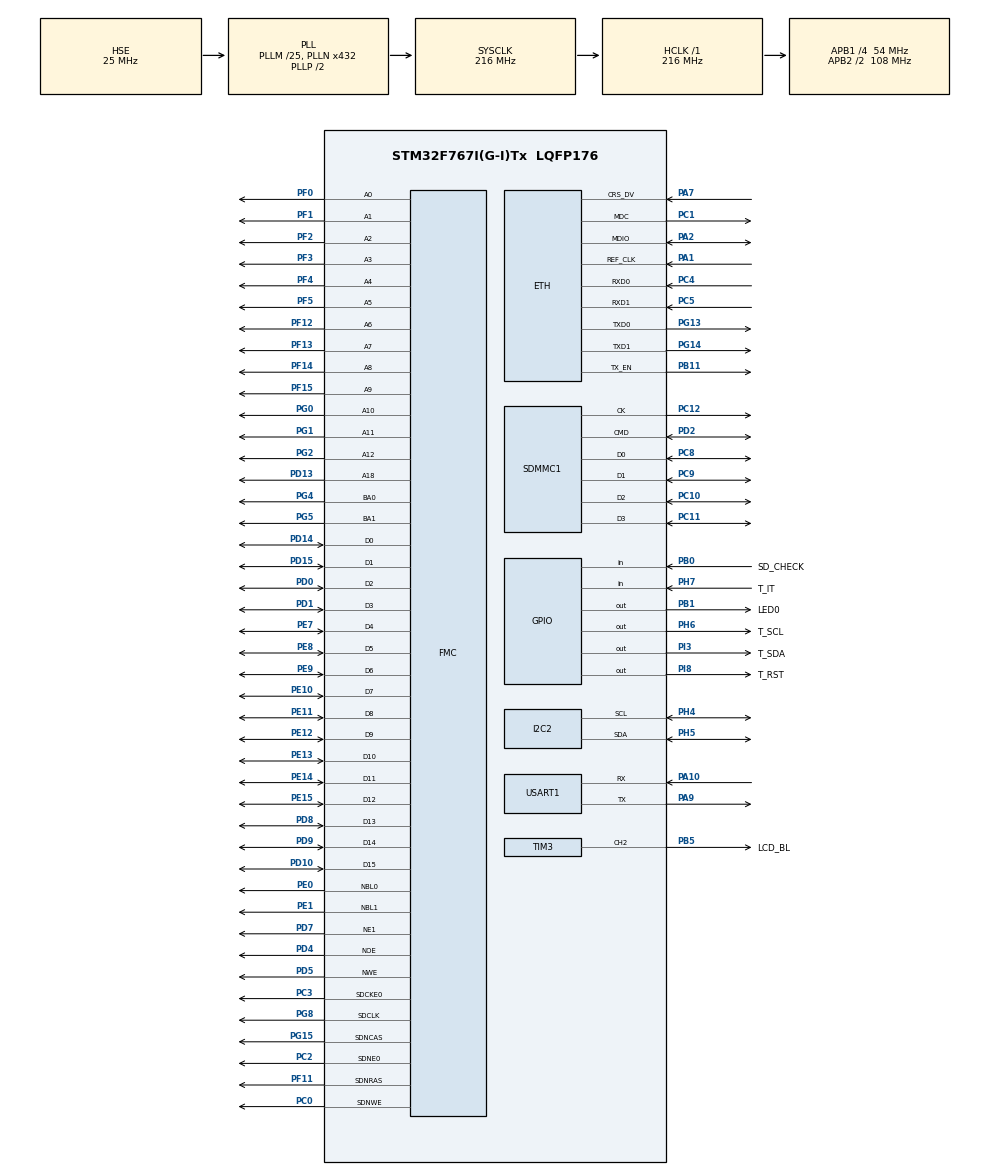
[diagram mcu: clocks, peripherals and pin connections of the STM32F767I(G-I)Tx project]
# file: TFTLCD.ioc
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PD7.Mode=NorPsramChipSelect1_1
SH.FMC_D7_DA7.1=FMC_D7,sd-16b-d1
SH.FMC_D7_DA7.0=FMC_D7,16b-d1
FATFS._USE_LFN=2
FMC.RCDDelay1=6
Dma.SDMMC1_RX.0.MemInc=DMA_MINC_ENABLE
FMC.SDClockPeriod1=FMC_SDRAM_CLOCK_PERIOD_2
SH.FMC_A0.0=FMC_A0,13b-sda1
FATFS0.BSP.api=Unknown
VP_FATFS_VS_SDIO.Mode=SDIO
PG8.Signal=FMC_SDCLK
PG4.Signal=FMC_A14_BA0
PC12.Signal=SDMMC1_CK
PH6.GPIO_Label=T_SCL
PG0.Signal=FMC_A10
FMC.LoadToActiveDelay1=2
PC5.Mode=RMII
SH.FMC_D5_DA5.1=FMC_D5,sd-16b-d1
SH.FMC_D5_DA5.0=FMC_D5,16b-d1
PG13.Signal=ETH_TXD0
SH.FMC_NWE.0=FMC_NWE,Lcd1
RCC.SYSCLKSource=RCC_SYSCLKSOURCE_PLLCLK
SH.FMC_A15_BA1.0=FMC_BA1,FourSdramBanks1
SH.FMC_D9_DA9.0=FMC_D9,16b-d1
SH.FMC_D9_DA9.1=FMC_D9,sd-16b-d1
NVIC.SDMMC1_IRQn=true\:5\:0\:false\:false\:true\:true\:true\:true
CORTEX_M7.Enable-Cortex_Memory_Protection_Unit_Region0_Settings=MPU_REGION_ENABLE
CORTEX_M7.IsBufferable-Cortex_Memory_Protection_Unit_Region1_Settings=MPU_ACCESS_BUFFERABLE
PH5.Signal=I2C2_SDA
SH.FMC_SDNWE.0=FMC_SDNWE,13b-sda1
SH.FMC_D11_DA11.0=FMC_D11,16b-d1
SH.FMC_D11_DA11.1=FMC_D11,sd-16b-d1
PD4.Signal=FMC_NOE
RCC.APB2TimFreq_Value=216000000
LWIP.LWIP_IGMP=0
PH1/OSC_OUT.Signal=RCC_OSC_OUT
PC3.Signal=FMC_SDCKE0
PD0.Signal=FMC_D2_DA2
PD8.Signal=FMC_D13_DA13
VP_JPEG_VS_JPEG.Mode=JPEG_Activate
PE1.Signal=FMC_NBL1
FATFS0.BSP.ip=GPIO
SH.FMC_A18.0=FMC_A18,A18_1
FATFS0.BSP.i2caddr=0
PG14.Mode=RMII
FMC.SelfRefreshTime1=6
LWIP.MEM_SIZE=1024 * 20
FMC.DataSetupTime1=85
PE9.Signal=FMC_D6_DA6
SH.FMC_A2.0=FMC_A2,13b-sda1
PI3.Signal=GPIO_Output
PB1.GPIO_Label=LED0
PC9.Mode=SD_4_bits_Wide_bus
SH.FMC_D1_DA1.0=FMC_D1,16b-d1
SH.FMC_D1_DA1.1=FMC_D1,sd-16b-d1
PF3.Signal=FMC_A3
PE10.Signal=FMC_D7_DA7
Mcu.Package=LQFP176
RCC.SDMMCClockSelection=RCC_SDMMC1CLKSOURCE_CLK48
PB1.Signal=GPIO_Output
NVIC.TimeBase=TIM4_IRQn
FATFS0.BSP.solution=PB0
FMC.ExtendedDataSetupTime1=15
Dma.SDMMC1_RX.0.PeriphBurst=DMA_PBURST_INC4
NVIC.TimeBaseIP=TIM4
PA10.Signal=USART1_RX
FMC.WriteRecoveryTime1=5
PC11.Mode=SD_4_bits_Wide_bus
SH.FMC_A1.0=FMC_A1,13b-sda1
RCC.APB2CLKDivider=RCC_HCLK_DIV2
SH.FMC_SDCLK.0=FMC_SDCLK,13b-sda1
FMC.ExtendedAddressSetupTime1=15
PF14.Signal=FMC_A8
RCC.APB1TimFreq_Value=108000000
CORTEX_M7.Enable-Cortex_Memory_Protection_Unit_Region1_Settings=MPU_REGION_ENABLE
TIM3.Pulse-PWM\ Generation2\ CH2=2048
Dma.SDMMC1_TX.1.MemInc=DMA_MINC_ENABLE
FMC.RowCycleDelay1=6
Dma.SDMMC1_RX.0.Mode=DMA_PFCTRL
FMC.ColumnBitsNumber1=FMC_SDRAM_COLUMN_BITS_NUM_9
PD15.Signal=FMC_D1_DA1
SH.FMC_D3_DA3.0=FMC_D3,16b-d1
SH.FMC_D3_DA3.1=FMC_D3,sd-16b-d1
CORTEX_M7.IsBufferable-Cortex_Memory_Protection_Unit_Region0_Settings=MPU_ACCESS_BUFFERABLE
PC4.Mode=RMII
Dma.SDMMC1_TX.1.Instance=DMA2_Stream6
FATFS0.BSP.STBoard=false
SH.FMC_A4.0=FMC_A4,13b-sda1
FREERTOS.Tasks01=lwipInitTask,24,512,lwipInitTaskEntry,Default,NULL,Dynamic,NULL,NULL;lvglTask,24,512,lvglTaskEntry,Default,NULL,Dynamic,NULL,NULL
Dma.SDMMC1_RX.0.PeriphInc=DMA_PINC_DISABLE
FMC.ExtendedMode1=FMC_EXTENDED_MODE_ENABLE
TIM3.AutoReloadPreload=TIM_AUTORELOAD_PRELOAD_DISABLE
PG5.Signal=FMC_A15_BA1
SH.FMC_D10_DA10.1=FMC_D10,sd-16b-d1
SH.FMC_D10_DA10.0=FMC_D10,16b-d1
FATFS0.BSP.mode=Input
PC2.Signal=FMC_SDNE0
PD7.Signal=FMC_NE1
PD1.Signal=FMC_D3_DA3
Dma.SDMMC1_RX.0.PeriphDataAlignment=DMA_PDATAALIGN_WORD
PC0.Signal=FMC_SDNWE
RCC.APB1CLKDivider=RCC_HCLK_DIV4
SH.FMC_NOE.0=FMC_NOE,Lcd1
PD10.Signal=FMC_D15_DA15
SH.FMC_A3.0=FMC_A3,13b-sda1
FMC.AddressSetupTime1=15
PI8.GPIO_Label=T_RST
FMC.CASLatency1=FMC_SDRAM_CAS_LATENCY_3
PB11.Mode=RMII
SH.FMC_D15_DA15.1=FMC_D15,sd-16b-d1
SH.FMC_D15_DA15.0=FMC_D15,16b-d1
PA9.Signal=USART1_TX
FMC.ExtendedBusTurnAroundDuration1=1
CORTEX_M7.BaseAddress-Cortex_Memory_Protection_Unit_Region0_Settings=0x60000000
NVIC.DMA2_Stream6_IRQn=true\:6\:0\:true\:false\:true\:true\:false\:true
FATFS.BSP.number=1
PC12.Mode=SD_4_bits_Wide_bus
FMC.ReadBurst1=FMC_SDRAM_RBURST_ENABLE
SH.FMC_A6.0=FMC_A6,13b-sda1
LWIP.LWIP_TFTP=0
PA1.Mode=RMII
PE14.Signal=FMC_D11_DA11
LWIP.MEMP_NUM_TCP_PCB=5
PE15.Signal=FMC_D12_DA12
PE8.Signal=FMC_D5_DA5
Dma.SDMMC1_RX.0.Direction=DMA_PERIPH_TO_MEMORY
CORTEX_M7.AccessPermission-Cortex_Memory_Protection_Unit_Region0_Settings=MPU_REGION_FULL_ACCESS
PF13.Signal=FMC_A7
Dma.SDMMC1_TX.1.FIFOMode=DMA_FIFOMODE_ENABLE
PA13.Mode=Serial_Wire
SH.FMC_SDNCAS.0=FMC_SDNCAS,13b-sda1
PH4.Mode=I2C
JPEG.JPEG_RGB_FORMAT=JPEG_RGB565
PC8.Mode=SD_4_bits_Wide_bus
PB5.Signal=S_TIM3_CH2
ETH.MediaInterface=ETH_MEDIA_INTERFACE_RMII
Dma.SDMMC1_TX.1.PeriphDataAlignment=DMA_PDATAALIGN_WORD
SH.FMC_A5.0=FMC_A5,13b-sda1
ProjectManager.HeapSize=0x400
LWIP.Version=v2.1.2_Cube
PH6.Signal=GPIO_Output
VP_SYS_VS_tim4.Mode=TIM4
FREERTOS.Timers01=lv_tick_timer,lv_tick_callback,osTimerPeriodic,Default,NULL,Dynamic,NULL
NVIC.PriorityGroup=NVIC_PRIORITYGROUP_4
TIM3.Channel-PWM\ Generation2\ CH2=TIM_CHANNEL_2
PF4.Signal=FMC_A4
PD2.Signal=SDMMC1_CMD
PB0.Signal=GPIO_Input
PC1.Signal=ETH_MDC
FATFS0.BSP.name=Detect_SDIO
PC1.Mode=RMII
Mcu.Family=STM32F7
PC3.Mode=SdramChipSelect1_1
SH.FMC_A8.0=FMC_A8,13b-sda1
RCC.CortexFreq_Value=216000000
SH.FMC_D14_DA14.0=FMC_D14,16b-d1
SH.FMC_D14_DA14.1=FMC_D14,sd-16b-d1
PG2.Signal=FMC_A12
PC10.Signal=SDMMC1_D2
I2C2.Timing=0x20404768
SH.FMC_NBL0.0=FMC_NBL0,Sd2ByteEnable1
SH.FMC_D6_DA6.1=FMC_D6,sd-16b-d1
SH.FMC_D6_DA6.0=FMC_D6,16b-d1
SDMMC1.ClockDiv=1
PB0.GPIO_Label=SD_CHECK
SH.FMC_A14_BA0.0=FMC_BA0,FourSdramBanks1
SH.FMC_A11.0=FMC_A11,13b-sda1
Dma.SDMMC1_RX.0.Instance=DMA2_Stream3
Dma.SDMMC1_RX.0.FIFOMode=DMA_FIFOMODE_ENABLE
Dma.SDMMC1_RX.0.Priority=DMA_PRIORITY_LOW
PB11.Signal=ETH_TX_EN
PG15.Signal=FMC_SDNCAS
ProjectManager.StackSize=0x400
VP_FREERTOS_VS_CMSIS_V2.Mode=CMSIS_V2
Dma.SDMMC1_TX.1.FIFOThreshold=DMA_FIFO_THRESHOLD_FULL
PD13.Signal=FMC_A18
SH.FMC_A7.0=FMC_A7,13b-sda1
PH0/OSC_IN.Mode=HSE-External-Oscillator
RCC.HCLKFreq_Value=216000000
TIM3.Period=4095
SH.FMC_NBL1.0=FMC_NBL1,Sd2ByteEnable1
PF12.Signal=FMC_A6
SH.FMC_A10.0=FMC_A10,13b-sda1
RCC.AHBFreq_Value=216000000
NVIC.ETH_IRQn=true\:5\:0\:false\:false\:true\:true\:false\:true
TIM3.ClockDivision=TIM_CLOCKDIVISION_DIV1
RCC.HSE_VALUE=25000000
SH.FMC_D8_DA8.0=FMC_D8,16b-d1
SH.FMC_D8_DA8.1=FMC_D8,sd-16b-d1
FMC.ExitSelfRefreshDelay1=8
FMC.RPDelay1=2
PI8.Signal=GPIO_Output
SH.FMC_D2_DA2.0=FMC_D2,16b-d1
SH.FMC_D2_DA2.1=FMC_D2,sd-16b-d1
FMC.BusTurnAroundDuration1=1
PE13.Signal=FMC_D10_DA10
PH7.GPIO_Label=T_IT
PA14.Mode=Serial_Wire
TIM3.Prescaler=6
PF11.Signal=FMC_SDNRAS
ETH.RxMode=ETH_RXINTERRUPT_MODE
PG13.Mode=RMII
FMC.ReadPipeDelay1=FMC_SDRAM_RPIPE_DELAY_1
SH.FMC_SDNRAS.0=FMC_SDNRAS,13b-sda1
PH1/OSC_OUT.Mode=HSE-External-Oscillator
FREERTOS.configTOTAL_HEAP_SIZE=51200
PB1.PinState=GPIO_PIN_SET
SH.FMC_D0_DA0.0=FMC_D0,16b-d1
SH.FMC_D0_DA0.1=FMC_D0,sd-16b-d1
CORTEX_M7.BaseAddress-Cortex_Memory_Protection_Unit_Region1_Settings=0xC0000000
SH.FMC_A9.0=FMC_A9,13b-sda1
SH.FMC_D4_DA4.1=FMC_D4,sd-16b-d1
SH.FMC_D4_DA4.0=FMC_D4,16b-d1
PF5.Signal=FMC_A5
CORTEX_M7.Size-Cortex_Memory_Protection_Unit_Region1_Settings=MPU_REGION_SIZE_32MB
PH7.Signal=GPIO_Input
LWIP.LWIP_MDNS=0
PB5.GPIO_Label=LCD_BL
Dma.Request1=SDMMC1_TX
PC5.Signal=ETH_RXD1
PF0.Signal=FMC_A0
PE7.Signal=FMC_D4_DA4
Dma.Request0=SDMMC1_RX
CORTEX_M7.IsShareable-Cortex_Memory_Protection_Unit_Region1_Settings=MPU_ACCESS_SHAREABLE
Dma.SDMMC1_RX.0.MemDataAlignment=DMA_MDATAALIGN_WORD
VP_TIM3_VS_ClockSourceINT.Mode=Internal
Dma.SDMMC1_TX.1.Direction=DMA_MEMORY_TO_PERIPH
SH.FMC_A12.0=FMC_A12,13b-sda1
RCC.PLLSourceVirtual=RCC_PLLSOURCE_HSE
PA7.Mode=RMII
ETH.PHY_User_Name=LAN8720A
PA10.Mode=Asynchronous
PH7.GPIO_PuPd=GPIO_NOPULL
PG1.Signal=FMC_A11
FATFS._USE_MUTEX=1
PC11.Signal=SDMMC1_D3
PC8.Signal=SDMMC1_D0
PC4.Signal=ETH_RXD0
PC10.Mode=SD_4_bits_Wide_bus
LWIP.LWIP_IPV6=1
PC2.Mode=SdramChipSelect1_1
PD9.Signal=FMC_D14_DA14
PD5.Signal=FMC_NWE
ETH.PhyAddress=0
VP_LWIP_VS_Enabled.Mode=Enabled
LWIP.LWIP_DNS=1
FATFS0.BSP.instance=PB0
LWIP.MEMP_NUM_UDP_PCB=4
USART1.VirtualMode-Asynchronous=VM_ASYNC
PA13.Signal=SYS_JTMS-SWDIO
CORTEX_M7.MPU_Control=MPU_PRIVILEGED_DEFAULT
PA9.Mode=Asynchronous
Dma.SDMMC1_TX.1.PeriphBurst=DMA_PBURST_INC4
PH4.Signal=I2C2_SCL
ETH.PHY_Name_RMII=userPHY
ProjectManager.TargetToolchain=Makefile
SH.FMC_D13_DA13.0=FMC_D13,16b-d1
FATFS._CODE_PAGE=936
SH.FMC_D13_DA13.1=FMC_D13,sd-16b-d1
PF2.Signal=FMC_A2
RCC.USBFreq_Value=48000000
NVIC.DMA2_Stream3_IRQn=true\:6\:0\:true\:false\:true\:true\:false\:true
PE11.Signal=FMC_D8_DA8
RCC.LSE_VALUE=32768
PA1.Signal=ETH_REF_CLK
PD2.Mode=SD_4_bits_Wide_bus
PG14.Signal=ETH_TXD1
SH.S_TIM3_CH2.0=TIM3_CH2,PWM Generation2 CH2
board=custom
RCC.VCOOutputFreq_Value=432000000
PH0/OSC_IN.Signal=RCC_OSC_IN
RCC.APB2Freq_Value=108000000
SH.FMC_D12_DA12.1=FMC_D12,sd-16b-d1
SH.FMC_D12_DA12.0=FMC_D12,16b-d1
Dma.SDMMC1_RX.0.MemBurst=DMA_MBURST_INC4
PF15.Signal=FMC_A9
Dma.SDMMC1_TX.1.Priority=DMA_PRIORITY_LOW
PF1.Signal=FMC_A1
Mcu.Name=STM32F767I(G-I)Tx
PE0.Signal=FMC_NBL0
CORTEX_M7.Size-Cortex_Memory_Protection_Unit_Region0_Settings=MPU_REGION_SIZE_256MB
PE12.Signal=FMC_D9_DA9
PA2.Signal=ETH_MDIO
CORTEX_M7.AccessPermission-Cortex_Memory_Protection_Unit_Region1_Settings=MPU_REGION_FULL_ACCESS
CORTEX_M7.IsCacheable-Cortex_Memory_Protection_Unit_Region1_Settings=MPU_ACCESS_CACHEABLE
PD14.Signal=FMC_D0_DA0
RCC.SYSCLKFreq_VALUE=216000000
Dma.SDMMC1_TX.1.MemBurst=DMA_MBURST_INC4
Dma.SDMMC1_RX.0.FIFOThreshold=DMA_FIFO_THRESHOLD_FULL
PA14.Signal=SYS_JTCK-SWCLK
Dma.SDMMC1_TX.1.MemDataAlignment=DMA_MDATAALIGN_WORD
RCC.HSI_VALUE=16000000
RCC.PLLQ=9
PI3.GPIO_Label=T_SDA
RCC.PLLM=25
RCC.PLLN=432
PA2.Mode=RMII
PH5.Mode=I2C
PC9.Signal=SDMMC1_D1
NVIC.TIM4_IRQn=true\:0\:0\:false\:false\:true\:false\:false\:true
RCC.APB1Freq_Value=54000000
Dma.SDMMC1_TX.1.Mode=DMA_PFCTRL
Dma.SDMMC1_TX.1.PeriphInc=DMA_PINC_DISABLE
PB0.GPIO_PuPd=GPIO_PULLDOWN
PA7.Signal=ETH_CRS_DV

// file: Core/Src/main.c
/* USER CODE BEGIN Header */
/**
  ******************************************************************************
  * @file           : main.c
  * @brief          : Main program body
  ******************************************************************************
  * @attention
  *
  * <h2><center>&copy; Copyright (c) 2021 STMicroelectronics.
  * All rights reserved.</center></h2>
  *
  * This software component is licensed by ST under BSD 3-Clause license,
  * the "License"; You may not use this file except in compliance with the
  * License. You may obtain a copy of the License at:
  *                        opensource.org/licenses/BSD-3-Clause
  *
  ******************************************************************************
  */
/* USER CODE END Header */
#include "main.h"
#include "cmsis_os.h"
#include "dma.h"
#include "fatfs.h"
#include "i2c.h"
#include "jpeg.h"
#include "lwip.h"
#include "sdmmc.h"
#include "tim.h"
#include "usart.h"
#include "gpio.h"
#include "fmc.h"

/* USER CODE BEGIN Includes */
#include "sdram.h"
#include "pcf8574.h"
/* USER CODE END Includes */

void SystemClock_Config(void);
static void MPU_Config(void);
void MX_FREERTOS_Init(void);

int main(void)
{

  /* MPU Configuration--------------------------------------------------------*/
  MPU_Config();

  /* MCU Configuration--------------------------------------------------------*/

  /* Reset of all peripherals, Initializes the Flash interface and the Systick. */
  HAL_Init();

  /* Configure the system clock */
  SystemClock_Config();

  /* Initialize all configured peripherals */
  MX_GPIO_Init();
  MX_DMA_Init();
  MX_FMC_Init();
  MX_USART1_UART_Init();
  MX_SDMMC1_SD_Init();
  MX_FATFS_Init();
  MX_TIM3_Init();
  MX_JPEG_Init();
  MX_I2C2_Init();
  /* USER CODE BEGIN 2 */
  sdram_init();
  pcf8574_init(&g_pcf8574, &g_pcf8574_iic_driver);
  /* USER CODE END 2 */

  /* Init scheduler */
  osKernelInitialize();  /* Call init function for freertos objects (in freertos.c) */
  MX_FREERTOS_Init();
  /* Start scheduler */
  osKernelStart();

  /* We should never get here as control is now taken by the scheduler */
  /* Infinite loop */
  while (1)
  {

  }
}

void SystemClock_Config(void)
{
  RCC_OscInitTypeDef RCC_OscInitStruct = {0};
  RCC_ClkInitTypeDef RCC_ClkInitStruct = {0};
  RCC_PeriphCLKInitTypeDef PeriphClkInitStruct = {0};

  /** Configure the main internal regulator output voltage
  */
  __HAL_RCC_PWR_CLK_ENABLE();
  __HAL_PWR_VOLTAGESCALING_CONFIG(PWR_REGULATOR_VOLTAGE_SCALE1);
  /** Initializes the RCC Oscillators according to the specified parameters
  * in the RCC_OscInitTypeDef structure.
  */
  RCC_OscInitStruct.OscillatorType = RCC_OSCILLATORTYPE_HSE;
  RCC_OscInitStruct.HSEState = RCC_HSE_ON;
  RCC_OscInitStruct.PLL.PLLState = RCC_PLL_ON;
  RCC_OscInitStruct.PLL.PLLSource = RCC_PLLSOURCE_HSE;
  RCC_OscInitStruct.PLL.PLLM = 25;
  RCC_OscInitStruct.PLL.PLLN = 432;
  RCC_OscInitStruct.PLL.PLLP = RCC_PLLP_DIV2;
  RCC_OscInitStruct.PLL.PLLQ = 9;
  if (HAL_RCC_OscConfig(&RCC_OscInitStruct) != HAL_OK)
  {
    Error_Handler();
  }
  /** Activate the Over-Drive mode
  */
  if (HAL_PWREx_EnableOverDrive() != HAL_OK)
  {
    Error_Handler();
  }
  /** Initializes the CPU, AHB and APB buses clocks
  */
  RCC_ClkInitStruct.ClockType = RCC_CLOCKTYPE_HCLK|RCC_CLOCKTYPE_SYSCLK
                              |RCC_CLOCKTYPE_PCLK1|RCC_CLOCKTYPE_PCLK2;
  RCC_ClkInitStruct.SYSCLKSource = RCC_SYSCLKSOURCE_PLLCLK;
  RCC_ClkInitStruct.AHBCLKDivider = RCC_SYSCLK_DIV1;
  RCC_ClkInitStruct.APB1CLKDivider = RCC_HCLK_DIV4;
  RCC_ClkInitStruct.APB2CLKDivider = RCC_HCLK_DIV2;

  if (HAL_RCC_ClockConfig(&RCC_ClkInitStruct, FLASH_LATENCY_7) != HAL_OK)
  {
    Error_Handler();
  }
  PeriphClkInitStruct.PeriphClockSelection = RCC_PERIPHCLK_USART1|RCC_PERIPHCLK_I2C2
                              |RCC_PERIPHCLK_SDMMC1|RCC_PERIPHCLK_CLK48;
  PeriphClkInitStruct.Usart1ClockSelection = RCC_USART1CLKSOURCE_PCLK2;
  PeriphClkInitStruct.I2c2ClockSelection = RCC_I2C2CLKSOURCE_PCLK1;
  PeriphClkInitStruct.Clk48ClockSelection = RCC_CLK48SOURCE_PLL;
  PeriphClkInitStruct.Sdmmc1ClockSelection = RCC_SDMMC1CLKSOURCE_CLK48;
  if (HAL_RCCEx_PeriphCLKConfig(&PeriphClkInitStruct) != HAL_OK)
  {
    Error_Handler();
  }
}

/* MPU Configuration */

void MPU_Config(void)
{
  MPU_Region_InitTypeDef MPU_InitStruct = {0};

  /* Disables the MPU */
  HAL_MPU_Disable();
  /** Initializes and configures the Region and the memory to be protected
  */
  MPU_InitStruct.Enable = MPU_REGION_ENABLE;
  MPU_InitStruct.Number = MPU_REGION_NUMBER0;
  MPU_InitStruct.BaseAddress = 0x60000000;
  MPU_InitStruct.Size = MPU_REGION_SIZE_256MB;
  MPU_InitStruct.SubRegionDisable = 0x0;
  MPU_InitStruct.TypeExtField = MPU_TEX_LEVEL0;
  MPU_InitStruct.AccessPermission = MPU_REGION_FULL_ACCESS;
  MPU_InitStruct.DisableExec = MPU_INSTRUCTION_ACCESS_ENABLE;
  MPU_InitStruct.IsShareable = MPU_ACCESS_NOT_SHAREABLE;
  MPU_InitStruct.IsCacheable = MPU_ACCESS_NOT_CACHEABLE;
  MPU_InitStruct.IsBufferable = MPU_ACCESS_BUFFERABLE;

  HAL_MPU_ConfigRegion(&MPU_InitStruct);
  /** Initializes and configures the Region and the memory to be protected
  */
  MPU_InitStruct.Enable = MPU_REGION_ENABLE;
  MPU_InitStruct.Number = MPU_REGION_NUMBER1;
  MPU_InitStruct.BaseAddress = 0xC0000000;
  MPU_InitStruct.Size = MPU_REGION_SIZE_32MB;
  MPU_InitStruct.SubRegionDisable = 0x0;
  MPU_InitStruct.TypeExtField = MPU_TEX_LEVEL0;
  MPU_InitStruct.AccessPermission = MPU_REGION_FULL_ACCESS;
  MPU_InitStruct.DisableExec = MPU_INSTRUCTION_ACCESS_ENABLE;
  MPU_InitStruct.IsShareable = MPU_ACCESS_SHAREABLE;
  MPU_InitStruct.IsCacheable = MPU_ACCESS_CACHEABLE;
  MPU_InitStruct.IsBufferable = MPU_ACCESS_BUFFERABLE;

  HAL_MPU_ConfigRegion(&MPU_InitStruct);
  /* Enables the MPU */
  HAL_MPU_Enable(MPU_PRIVILEGED_DEFAULT);

}
void HAL_TIM_PeriodElapsedCallback(TIM_HandleTypeDef *htim)
{
  if (htim->Instance == TIM4) {
    HAL_IncTick();
  }
}

void Error_Handler(void)
{
  __disable_irq();
  while (1)
  {
  }
}

/************************ (C) COPYRIGHT STMicroelectronics *****END OF FILE****/

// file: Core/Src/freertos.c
/* USER CODE BEGIN Header */
/**
  ******************************************************************************
  * File Name          : freertos.c
  * Description        : Code for freertos applications
  ******************************************************************************
  * @attention
  *
  * <h2><center>&copy; Copyright (c) 2021 STMicroelectronics.
  * All rights reserved.</center></h2>
  *
  * This software component is licensed by ST under Ultimate Liberty license
  * SLA0044, the "License"; You may not use this file except in compliance with
  * the License. You may obtain a copy of the License at:
  *                             www.st.com/SLA0044
  *
  ******************************************************************************
  */
/* USER CODE END Header */

#include "FreeRTOS.h"
#include "task.h"
#include "main.h"
#include "cmsis_os.h"

/* USER CODE BEGIN Includes */
#include "lvgl.h"
#include "lv_port_indev.h"
#include "lv_port_disp.h"
#include "lv_port_fs.h"
#include "lv_demo.h"
#include <stdio.h>
/* USER CODE END Includes */

/* Definitions for lwipInitTask */
osThreadId_t lwipInitTaskHandle;
const osThreadAttr_t lwipInitTask_attributes = {
  .name = "lwipInitTask",
  .priority = (osPriority_t) osPriorityNormal,
  .stack_size = 512 * 4
};
/* Definitions for lvglTask */
osThreadId_t lvglTaskHandle;
const osThreadAttr_t lvglTask_attributes = {
  .name = "lvglTask",
  .priority = (osPriority_t) osPriorityNormal,
  .stack_size = 512 * 4
};
/* Definitions for lv_tick_timer */
osTimerId_t lv_tick_timerHandle;
const osTimerAttr_t lv_tick_timer_attributes = {
  .name = "lv_tick_timer"
};

void lwipInitTaskEntry(void *argument);
void lvglTaskEntry(void *argument);
void lv_tick_callback(void *argument);

extern void MX_LWIP_Init(void);
void MX_FREERTOS_Init(void); /* (MISRA C 2004 rule 8.1) */

void MX_FREERTOS_Init(void) {

  /* Create the timer(s) */
  /* creation of lv_tick_timer */
  lv_tick_timerHandle = osTimerNew(lv_tick_callback, osTimerPeriodic, NULL, &lv_tick_timer_attributes);

  /* Create the thread(s) */
  /* creation of lwipInitTask */
  lwipInitTaskHandle = osThreadNew(lwipInitTaskEntry, NULL, &lwipInitTask_attributes);

  /* creation of lvglTask */
  lvglTaskHandle = osThreadNew(lvglTaskEntry, NULL, &lvglTask_attributes);

}

void lwipInitTaskEntry(void *argument)
{
  /* init code for LWIP */
  MX_LWIP_Init();
  /* USER CODE BEGIN lwipInitTaskEntry */
  osThreadExit();
  /* Infinite loop */
  for(;;)
  {
    osDelay(1);
  }
  /* USER CODE END lwipInitTaskEntry */
}

void lvglTaskEntry(void *argument)
{
  /* USER CODE BEGIN lvglTaskEntry */
  osTimerStart(lv_tick_timerHandle,5);
  lv_init();
  lv_port_fs_init();
  lv_port_disp_init();
  lv_port_indev_init();
  lv_demo_widgets();
  /* Infinite loop */
  for(;;)
  {
    lv_timer_handler();
    osDelay(5);
  }
  /* USER CODE END lvglTaskEntry */
}

/* lv_tick_callback function */
void lv_tick_callback(void *argument)
{
  /* USER CODE BEGIN lv_tick_callback */
  lv_tick_inc(5);
  /* USER CODE END lv_tick_callback */
}

/************************ (C) COPYRIGHT STMicroelectronics *****END OF FILE****/
